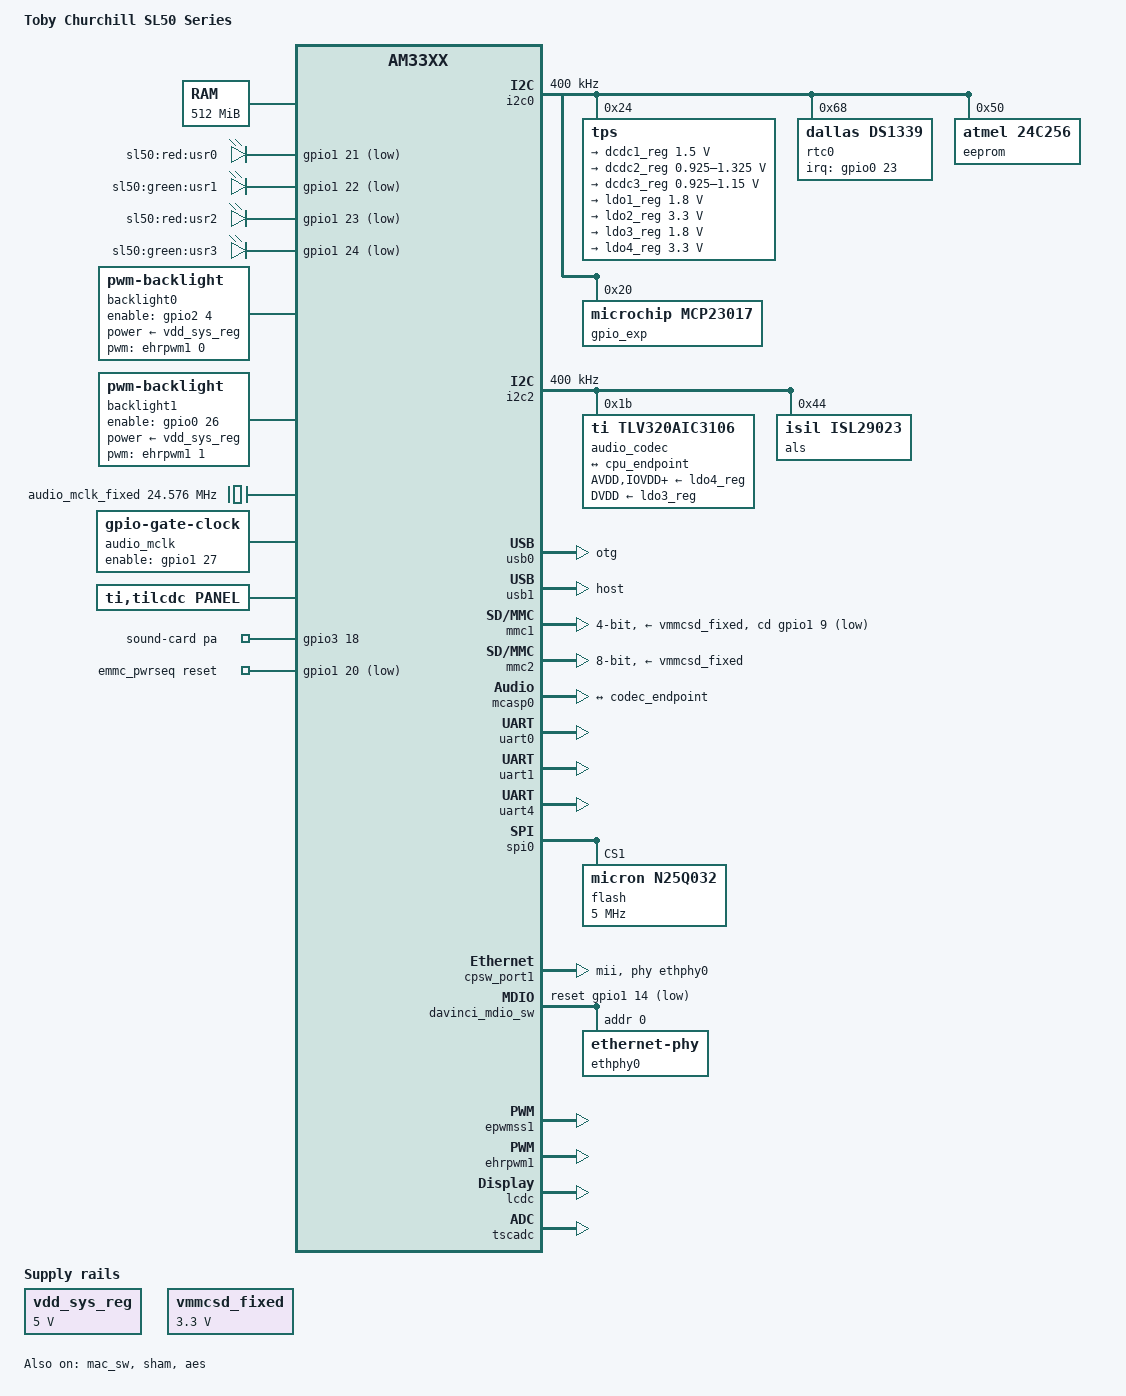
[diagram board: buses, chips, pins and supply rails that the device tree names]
/dts-v1/;
#include "am33xx.dtsi"
#include <dt-bindings/pwm/pwm.h>
#include <dt-bindings/interrupt-controller/irq.h>
/ {
	model = "Toby Churchill SL50 Series";
	compatible = "tcl,am335x-sl50", "ti,am33xx";
	cpus {
		cpu@0 {
			cpu0-supply = <&dcdc2_reg>;
		};
	};
	memory@80000000 {
		device_type = "memory";
		reg = <0x80000000 0x20000000>;  
	};
	chosen {
		stdout-path = &uart0;
	};
	leds {
		compatible = "gpio-leds";
		pinctrl-names = "default";
		pinctrl-0 = <&led_pins>;
		led0 {
			label = "sl50:red:usr0";
			gpios = <&gpio1 21 GPIO_ACTIVE_LOW>;
			default-state = "off";
		};
		led1 {
			label = "sl50:green:usr1";
			gpios = <&gpio1 22 GPIO_ACTIVE_LOW>;
			default-state = "off";
		};
		led2 {
			label = "sl50:red:usr2";
			gpios = <&gpio1 23 GPIO_ACTIVE_LOW>;
			default-state = "off";
		};
		led3 {
			label = "sl50:green:usr3";
			gpios = <&gpio1 24 GPIO_ACTIVE_LOW>;
			default-state = "off";
		};
	};
	backlight0: disp0 {
		compatible = "pwm-backlight";
		pinctrl-names = "default";
		pinctrl-0 = <&backlight0_pins>;
		pwms = <&ehrpwm1 0 500000 PWM_POLARITY_INVERTED>;
		brightness-levels = < 0  1  2  3  4  5  6  7  8  9
				     10 11 12 13 14 15 16 17 18 19
				     20 21 22 23 24 25 26 27 28 29
				     30 31 32 33 34 35 36 37 38 39
				     40 41 42 43 44 45 46 47 48 49
				     50 51 52 53 54 55 56 57 58 59
				     60 61 62 63 64 65 66 67 68 69
				     70 71 72 73 74 75 76 77 78 79
				     80 81 82 83 84 85 86 87 88 89
				     90 91 92 93 94 95 96 97 98 99
				    100>;
		default-brightness-level = <50>;
		enable-gpios = <&gpio2 4 GPIO_ACTIVE_HIGH>;
		power-supply = <&vdd_sys_reg>;
	};
	backlight1: disp1 {
		compatible = "pwm-backlight";
		pinctrl-names = "default";
		pinctrl-0 = <&backlight1_pins>;
		pwms = <&ehrpwm1 1 500000 PWM_POLARITY_INVERTED>;
		brightness-levels = < 0  1  2  3  4  5  6  7  8  9
				     10 11 12 13 14 15 16 17 18 19
				     20 21 22 23 24 25 26 27 28 29
				     30 31 32 33 34 35 36 37 38 39
				     40 41 42 43 44 45 46 47 48 49
				     50 51 52 53 54 55 56 57 58 59
				     60 61 62 63 64 65 66 67 68 69
				     70 71 72 73 74 75 76 77 78 79
				     80 81 82 83 84 85 86 87 88 89
				     90 91 92 93 94 95 96 97 98 99
				    100>;
		default-brightness-level = <50>;
		enable-gpios = <&gpio0 26 GPIO_ACTIVE_HIGH>;
		power-supply = <&vdd_sys_reg>;
	};
	clocks {
		compatible = "simple-bus";
		#address-cells = <1>;
		#size-cells = <0>;
		audio_mclk_fixed: oscillator@0 {
			compatible = "fixed-clock";
			#clock-cells = <0>;
			clock-frequency  = <24576000>;	 
		};
		audio_mclk: audio_mclk_gate@0 {
			compatible = "gpio-gate-clock";
			#clock-cells = <0>;
			pinctrl-names = "default";
			pinctrl-0 = <&audio_mclk_pins>;
			clocks = <&audio_mclk_fixed>;
			enable-gpios = <&gpio1 27 0>;
		};
	};
	panel: lcd_panel {
		compatible = "ti,tilcdc,panel";
		pinctrl-names = "default";
		pinctrl-0 = <&lcd_pins>;
		panel-info {
			ac-bias = <255>;
			ac-bias-intrpt = <0>;
			dma-burst-sz = <16>;
			bpp = <16>;
			fdd = <0x80>;
			tft-alt-mode = <0>;
			mono-8bit-mode = <0>;
			sync-edge = <0>;
			sync-ctrl = <1>;
			raster-order = <0>;
			fifo-th = <0>;
		};
		display-timings {
			native-mode = <&timing0>;
			timing0: 960x128 {
				clock-frequency = <18000000>;
				hactive = <960>;
				vactive = <272>;
				hback-porch = <40>;
				hfront-porch = <16>;
				hsync-len = <24>;
				hsync-active = <0>;
				vback-porch = <3>;
				vfront-porch = <8>;
				vsync-len = <4>;
				vsync-active = <0>;
			};
		};
	};
	sound {
		compatible = "audio-graph-card";
		label = "sound-card";
		pinctrl-names = "default";
		pinctrl-0 = <&audio_pa_pins>;
		widgets = "Headphone", "Headphone Jack",
			  "Speaker", "Speaker External",
			  "Line", "Line In",
			  "Microphone", "Microphone Jack";
		routing = "Headphone Jack",	"HPLOUT",
			  "Headphone Jack",	"HPROUT",
			  "Amplifier",		"MONO_LOUT",
			  "Speaker External",	"Amplifier",
			  "LINE1R",		"Line In",
			  "LINE1L",		"Line In",
			  "MIC3L",		"Microphone Jack",
			  "MIC3R",		"Microphone Jack",
			  "Microphone Jack",	"Mic Bias";
		dais = <&cpu_port>;
		pa-gpios = <&gpio3 18 GPIO_ACTIVE_HIGH>;
	};
	emmc_pwrseq: pwrseq@0 {
		compatible = "mmc-pwrseq-emmc";
		pinctrl-names = "default";
		pinctrl-0 = <&emmc_pwrseq_pins>;
		reset-gpios = <&gpio1 20 GPIO_ACTIVE_LOW>;
	};
	vdd_sys_reg: regulator@0 {
		compatible = "regulator-fixed";
		regulator-name = "vdd_sys_reg";
		regulator-min-microvolt = <5000000>;
		regulator-max-microvolt = <5000000>;
		regulator-always-on;
	};
	vmmcsd_fixed: fixedregulator0 {
		compatible = "regulator-fixed";
		regulator-name = "vmmcsd_fixed";
		regulator-min-microvolt = <3300000>;
		regulator-max-microvolt = <3300000>;
	};
};
&am33xx_pinmux {
	pinctrl-names = "default";
	pinctrl-0 = <&lwb_pins>;
	audio_pins: audio-pins {
		pinctrl-single,pins = <
			AM33XX_PADCONF(AM335X_PIN_MCASP0_AHCLKX, PIN_INPUT_PULLDOWN, MUX_MODE0)
			AM33XX_PADCONF(AM335X_PIN_MCASP0_FSX, PIN_INPUT_PULLDOWN, MUX_MODE0)
			AM33XX_PADCONF(AM335X_PIN_MCASP0_ACLKX, PIN_INPUT_PULLDOWN, MUX_MODE0)
			AM33XX_PADCONF(AM335X_PIN_MCASP0_AXR0, PIN_INPUT_PULLDOWN, MUX_MODE0)
			AM33XX_PADCONF(AM335X_PIN_MCASP0_AHCLKR, PIN_OUTPUT_PULLDOWN, MUX_MODE2)
		>;
	};
	audio_pa_pins: audio-pa-pins {
		pinctrl-single,pins = <
			AM33XX_PADCONF(AM335X_PIN_MCASP0_ACLKR, PIN_INPUT_PULLDOWN, MUX_MODE7)	 
		>;
	};
	audio_mclk_pins: audio-mclk-pins {
		pinctrl-single,pins = <
			AM33XX_PADCONF(AM335X_PIN_GPMC_A11, PIN_INPUT_PULLDOWN, MUX_MODE7)	 
		>;
	};
	backlight0_pins: backlight0-pins {
		pinctrl-single,pins = <
			AM33XX_PADCONF(AM335X_PIN_GPMC_WEN, PIN_OUTPUT, MUX_MODE7)	 
		>;
	};
	backlight1_pins: backlight1-pins {
		pinctrl-single,pins = <
			AM33XX_PADCONF(AM335X_PIN_GPMC_AD10, PIN_OUTPUT, MUX_MODE7)      
		>;
	};
	lcd_pins: lcd-pins {
		pinctrl-single,pins = <
			AM33XX_PADCONF(AM335X_PIN_LCD_DATA0, PIN_OUTPUT, MUX_MODE0)
			AM33XX_PADCONF(AM335X_PIN_LCD_DATA1, PIN_OUTPUT, MUX_MODE0)
			AM33XX_PADCONF(AM335X_PIN_LCD_DATA2, PIN_OUTPUT, MUX_MODE0)
			AM33XX_PADCONF(AM335X_PIN_LCD_DATA3, PIN_OUTPUT, MUX_MODE0)
			AM33XX_PADCONF(AM335X_PIN_LCD_DATA4, PIN_OUTPUT, MUX_MODE0)
			AM33XX_PADCONF(AM335X_PIN_LCD_DATA5, PIN_OUTPUT, MUX_MODE0)
			AM33XX_PADCONF(AM335X_PIN_LCD_DATA6, PIN_OUTPUT, MUX_MODE0)
			AM33XX_PADCONF(AM335X_PIN_LCD_DATA7, PIN_OUTPUT, MUX_MODE0)
			AM33XX_PADCONF(AM335X_PIN_LCD_DATA8, PIN_OUTPUT, MUX_MODE0)
			AM33XX_PADCONF(AM335X_PIN_LCD_DATA9, PIN_OUTPUT, MUX_MODE0)
			AM33XX_PADCONF(AM335X_PIN_LCD_DATA10, PIN_OUTPUT, MUX_MODE0)
			AM33XX_PADCONF(AM335X_PIN_LCD_DATA11, PIN_OUTPUT, MUX_MODE0)
			AM33XX_PADCONF(AM335X_PIN_LCD_DATA12, PIN_OUTPUT, MUX_MODE0)
			AM33XX_PADCONF(AM335X_PIN_LCD_DATA13, PIN_OUTPUT, MUX_MODE0)
			AM33XX_PADCONF(AM335X_PIN_LCD_DATA14, PIN_OUTPUT, MUX_MODE0)
			AM33XX_PADCONF(AM335X_PIN_LCD_DATA15, PIN_OUTPUT, MUX_MODE0)
			AM33XX_PADCONF(AM335X_PIN_LCD_VSYNC, PIN_OUTPUT_PULLDOWN, MUX_MODE0)
			AM33XX_PADCONF(AM335X_PIN_LCD_HSYNC, PIN_OUTPUT_PULLDOWN, MUX_MODE0)
			AM33XX_PADCONF(AM335X_PIN_LCD_PCLK, PIN_OUTPUT_PULLDOWN, MUX_MODE0)
			AM33XX_PADCONF(AM335X_PIN_LCD_AC_BIAS_EN, PIN_OUTPUT_PULLDOWN, MUX_MODE0)
		>;
	};
	led_pins: led-pins {
		pinctrl-single,pins = <
			AM33XX_PADCONF(AM335X_PIN_GPMC_A5, PIN_OUTPUT, MUX_MODE7)	 
			AM33XX_PADCONF(AM335X_PIN_GPMC_A6, PIN_OUTPUT, MUX_MODE7)	 
			AM33XX_PADCONF(AM335X_PIN_GPMC_A7, PIN_OUTPUT, MUX_MODE7)	 
			AM33XX_PADCONF(AM335X_PIN_GPMC_A8, PIN_OUTPUT, MUX_MODE7)	 
		>;
	};
	uart0_pins: uart0-pins {
		pinctrl-single,pins = <
			AM33XX_PADCONF(AM335X_PIN_UART0_RXD, PIN_INPUT_PULLUP, MUX_MODE0)
			AM33XX_PADCONF(AM335X_PIN_UART0_TXD, PIN_OUTPUT_PULLDOWN, MUX_MODE0)
		>;
	};
	uart1_pins: uart1-pins {
		pinctrl-single,pins = <
			AM33XX_PADCONF(AM335X_PIN_UART1_RXD, PIN_INPUT_PULLUP, MUX_MODE0)
			AM33XX_PADCONF(AM335X_PIN_UART1_TXD, PIN_OUTPUT_PULLDOWN, MUX_MODE0)
		>;
	};
	uart4_pins: uart4-pins {
		pinctrl-single,pins = <
			AM33XX_PADCONF(AM335X_PIN_GPMC_WAIT0, PIN_INPUT_PULLUP, MUX_MODE6)	 
			AM33XX_PADCONF(AM335X_PIN_GPMC_WPN, PIN_OUTPUT_PULLDOWN, MUX_MODE6)	 
		>;
	};
	i2c0_pins: i2c0-pins {
		pinctrl-single,pins = <
			AM33XX_PADCONF(AM335X_PIN_I2C0_SDA, PIN_INPUT_PULLUP, MUX_MODE0)
			AM33XX_PADCONF(AM335X_PIN_I2C0_SCL, PIN_INPUT_PULLUP, MUX_MODE0)
		>;
	};
	i2c2_pins: i2c2-pins {
		pinctrl-single,pins = <
			AM33XX_PADCONF(AM335X_PIN_UART1_CTSN, PIN_INPUT_PULLUP, MUX_MODE3)	 
			AM33XX_PADCONF(AM335X_PIN_UART1_RTSN, PIN_INPUT_PULLUP, MUX_MODE3)	 
		>;
	};
	cpsw_default: cpsw-default-pins {
		pinctrl-single,pins = <
			AM33XX_PADCONF(AM335X_PIN_MII1_RX_ER, PIN_INPUT_PULLUP, MUX_MODE0)
			AM33XX_PADCONF(AM335X_PIN_MII1_TX_EN, PIN_OUTPUT_PULLDOWN, MUX_MODE0)
			AM33XX_PADCONF(AM335X_PIN_MII1_RX_DV, PIN_INPUT_PULLUP, MUX_MODE0)
			AM33XX_PADCONF(AM335X_PIN_MII1_TXD3, PIN_OUTPUT_PULLDOWN, MUX_MODE0)
			AM33XX_PADCONF(AM335X_PIN_MII1_TXD2, PIN_OUTPUT_PULLDOWN, MUX_MODE0)
			AM33XX_PADCONF(AM335X_PIN_MII1_TXD1, PIN_OUTPUT_PULLDOWN, MUX_MODE0)
			AM33XX_PADCONF(AM335X_PIN_MII1_TXD0, PIN_OUTPUT_PULLDOWN, MUX_MODE0)
			AM33XX_PADCONF(AM335X_PIN_MII1_TX_CLK, PIN_INPUT_PULLUP, MUX_MODE0)
			AM33XX_PADCONF(AM335X_PIN_MII1_RX_CLK, PIN_INPUT_PULLUP, MUX_MODE0)
			AM33XX_PADCONF(AM335X_PIN_MII1_RXD3, PIN_INPUT_PULLUP, MUX_MODE0)
			AM33XX_PADCONF(AM335X_PIN_MII1_RXD2, PIN_INPUT_PULLUP, MUX_MODE0)
			AM33XX_PADCONF(AM335X_PIN_MII1_RXD1, PIN_INPUT_PULLUP, MUX_MODE0)
			AM33XX_PADCONF(AM335X_PIN_MII1_RXD0, PIN_INPUT_PULLUP, MUX_MODE0)
		>;
	};
	cpsw_sleep: cpsw-sleep-pins {
		pinctrl-single,pins = <
			AM33XX_PADCONF(AM335X_PIN_MII1_RX_ER, PIN_INPUT_PULLDOWN, MUX_MODE7)
			AM33XX_PADCONF(AM335X_PIN_MII1_TX_EN, PIN_INPUT_PULLDOWN, MUX_MODE7)
			AM33XX_PADCONF(AM335X_PIN_MII1_RX_DV, PIN_INPUT_PULLDOWN, MUX_MODE7)
			AM33XX_PADCONF(AM335X_PIN_MII1_TXD3, PIN_INPUT_PULLDOWN, MUX_MODE7)
			AM33XX_PADCONF(AM335X_PIN_MII1_TXD2, PIN_INPUT_PULLDOWN, MUX_MODE7)
			AM33XX_PADCONF(AM335X_PIN_MII1_TXD1, PIN_INPUT_PULLDOWN, MUX_MODE7)
			AM33XX_PADCONF(AM335X_PIN_MII1_TXD0, PIN_INPUT_PULLDOWN, MUX_MODE7)
			AM33XX_PADCONF(AM335X_PIN_MII1_TX_CLK, PIN_INPUT_PULLDOWN, MUX_MODE7)
			AM33XX_PADCONF(AM335X_PIN_MII1_RX_CLK, PIN_INPUT_PULLDOWN, MUX_MODE7)
			AM33XX_PADCONF(AM335X_PIN_MII1_RXD3, PIN_INPUT_PULLDOWN, MUX_MODE7)
			AM33XX_PADCONF(AM335X_PIN_MII1_RXD2, PIN_INPUT_PULLDOWN, MUX_MODE7)
			AM33XX_PADCONF(AM335X_PIN_MII1_RXD1, PIN_INPUT_PULLDOWN, MUX_MODE7)
			AM33XX_PADCONF(AM335X_PIN_MII1_RXD0, PIN_INPUT_PULLDOWN, MUX_MODE7)
		>;
	};
	davinci_mdio_default: davinci-mdio-default-pins {
		pinctrl-single,pins = <
			AM33XX_PADCONF(AM335X_PIN_MDIO, PIN_INPUT_PULLUP | SLEWCTRL_FAST, MUX_MODE0)
			AM33XX_PADCONF(AM335X_PIN_MDC, PIN_OUTPUT_PULLUP, MUX_MODE0)
			AM33XX_PADCONF(AM335X_PIN_GPMC_AD14, PIN_INPUT_PULLUP, MUX_MODE7)	 
		>;
	};
	davinci_mdio_sleep: davinci-mdio-sleep-pins {
		pinctrl-single,pins = <
			AM33XX_PADCONF(AM335X_PIN_MDIO, PIN_INPUT_PULLDOWN, MUX_MODE7)
			AM33XX_PADCONF(AM335X_PIN_MDC, PIN_INPUT_PULLDOWN, MUX_MODE7)
		>;
	};
	mmc1_pins: mmc1-pins {
		pinctrl-single,pins = <
			AM33XX_PADCONF(AM335X_PIN_UART0_RTSN, PIN_INPUT, MUX_MODE7)		 
		>;
	};
	emmc_pwrseq_pins: emmc-pwrseq-pins {
		pinctrl-single,pins = <
			AM33XX_PADCONF(AM335X_PIN_GPMC_A4, PIN_OUTPUT_PULLUP, MUX_MODE7)	 
		>;
	};
	emmc_pins: emmc-pins {
		pinctrl-single,pins = <
			AM33XX_PADCONF(AM335X_PIN_GPMC_CSN1, PIN_INPUT_PULLUP, MUX_MODE2)	 
			AM33XX_PADCONF(AM335X_PIN_GPMC_CSN2, PIN_INPUT_PULLUP, MUX_MODE2)	 
			AM33XX_PADCONF(AM335X_PIN_GPMC_AD0, PIN_INPUT_PULLUP, MUX_MODE1)	 
			AM33XX_PADCONF(AM335X_PIN_GPMC_AD1, PIN_INPUT_PULLUP, MUX_MODE1)	 
			AM33XX_PADCONF(AM335X_PIN_GPMC_AD2, PIN_INPUT_PULLUP, MUX_MODE1)	 
			AM33XX_PADCONF(AM335X_PIN_GPMC_AD3, PIN_INPUT_PULLUP, MUX_MODE1)	 
			AM33XX_PADCONF(AM335X_PIN_GPMC_AD4, PIN_INPUT_PULLUP, MUX_MODE1)	 
			AM33XX_PADCONF(AM335X_PIN_GPMC_AD5, PIN_INPUT_PULLUP, MUX_MODE1) 	 
			AM33XX_PADCONF(AM335X_PIN_GPMC_AD6, PIN_INPUT_PULLUP, MUX_MODE1)	 
			AM33XX_PADCONF(AM335X_PIN_GPMC_AD7, PIN_INPUT_PULLUP, MUX_MODE1)	 
		>;
	};
	ehrpwm1_pins: ehrpwm1a-pins {
		pinctrl-single,pins = <
			AM33XX_PADCONF(AM335X_PIN_GPMC_A2, PIN_OUTPUT, MUX_MODE6)	 
			AM33XX_PADCONF(AM335X_PIN_GPMC_A3, PIN_OUTPUT, MUX_MODE6)	 
		>;
	};
	rtc0_irq_pins: rtc0-irq-pins {
		pinctrl-single,pins = <
			AM33XX_PADCONF(AM335X_PIN_GPMC_AD9, PIN_INPUT_PULLUP, MUX_MODE7)      
		>;
	};
	spi0_pins: spi0-pins {
		pinctrl-single,pins = <
			AM33XX_PADCONF(AM335X_PIN_SPI0_D0, PIN_INPUT_PULLUP, MUX_MODE0)	 
			AM33XX_PADCONF(AM335X_PIN_SPI0_D1, PIN_INPUT_PULLUP, MUX_MODE0)	 
			AM33XX_PADCONF(AM335X_PIN_SPI0_SCLK, PIN_INPUT_PULLUP, MUX_MODE0)
			AM33XX_PADCONF(AM335X_PIN_SPI0_CS0, PIN_INPUT_PULLUP, MUX_MODE0)	 
			AM33XX_PADCONF(AM335X_PIN_SPI0_CS1, PIN_INPUT_PULLUP, MUX_MODE0)	 
		>;
	};
	lwb_pins: lwb-pins {
		pinctrl-single,pins = <
			AM33XX_PADCONF(AM335X_PIN_GPMC_AD12, PIN_INPUT_PULLUP, MUX_MODE7)	 
			AM33XX_PADCONF(AM335X_PIN_GPMC_AD13, PIN_INPUT_PULLUP, MUX_MODE7)	 
			AM33XX_PADCONF(AM335X_PIN_GPMC_A1, PIN_INPUT_PULLUP, MUX_MODE7)	 
			AM33XX_PADCONF(AM335X_PIN_GPMC_A0, PIN_INPUT_PULLUP, MUX_MODE7)	 
			AM33XX_PADCONF(AM335X_PIN_GPMC_AD15, PIN_INPUT_PULLUP, MUX_MODE7)	 
			AM33XX_PADCONF(AM335X_PIN_GPMC_AD8, PIN_INPUT_PULLUP, MUX_MODE7)	 
			AM33XX_PADCONF(AM335X_PIN_GPMC_A0, PIN_INPUT_PULLUP, MUX_MODE7)	 
			AM33XX_PADCONF(AM335X_PIN_GPMC_A1, PIN_INPUT_PULLDOWN, MUX_MODE7)	 
			AM33XX_PADCONF(AM335X_PIN_GPMC_A9, PIN_INPUT_PULLUP, MUX_MODE7)	 
			AM33XX_PADCONF(AM335X_PIN_GPMC_A10, PIN_INPUT_PULLDOWN, MUX_MODE7)	 
		>;
	};
};
&i2c0 {
	status = "okay";
	pinctrl-names = "default";
	pinctrl-0 = <&i2c0_pins>;
	clock-frequency = <400000>;
	tps: tps@24 {
		reg = <0x24>;
	};
	rtc0: rtc@68 {
		compatible = "dallas,ds1339";
		pinctrl-names = "default";
		pinctrl-0 = <&rtc0_irq_pins>;
		interrupt-parent = <&gpio0>;
		interrupts = <23 IRQ_TYPE_EDGE_FALLING>;  
		wakeup-source;
		trickle-resistor-ohms = <2000>;
		reg = <0x68>;
	};
	eeprom: eeprom@50 {
		compatible = "atmel,24c256";
		reg = <0x50>;
	};
	gpio_exp: mcp23017@20 {
		compatible = "microchip,mcp23017";
		reg = <0x20>;
	};
};
&i2c2 {
	status = "okay";
	pinctrl-names = "default";
	pinctrl-0 = <&i2c2_pins>;
	clock-frequency = <400000>;
	audio_codec: tlv320aic3106@1b {
		status = "okay";
		compatible = "ti,tlv320aic3106";
		#sound-dai-cells = <0>;
		reg = <0x1b>;
		ai3x-micbias-vg = <2>;   
		AVDD-supply = <&ldo4_reg>;
		IOVDD-supply = <&ldo4_reg>;
		DRVDD-supply = <&ldo4_reg>;
		DVDD-supply = <&ldo3_reg>;
		codec_port: port {
			codec_endpoint: endpoint {
				remote-endpoint = <&cpu_endpoint>;
				clocks = <&audio_mclk>;
			};
		};
	};
	als: isl29023@44 {
		compatible = "isil,isl29023";
		reg = <0x44>;
	};
};
&rtc {
	status = "disabled";
};
&usb0 {
	dr_mode = "otg";
};
&usb1 {
	dr_mode = "host";
};
&mmc1 {
	status = "okay";
	pinctrl-names = "default";
	pinctrl-0 = <&mmc1_pins>;
	bus-width = <4>;
	cd-gpios = <&gpio1 9 GPIO_ACTIVE_LOW>;
	vmmc-supply = <&vmmcsd_fixed>;
};
&mmc2 {
	status = "okay";
	pinctrl-names = "default";
	pinctrl-0 = <&emmc_pins>;
	bus-width = <8>;
	vmmc-supply = <&vmmcsd_fixed>;
	mmc-pwrseq = <&emmc_pwrseq>;
};
&mcasp0 {
	status = "okay";
	pinctrl-names = "default";
	pinctrl-0 = <&audio_pins>;
	#sound-dai-cells = <0>;
	op-mode = <0>;   
	tdm-slots = <2>;
	serial-dir = <   
		0 0 1 2
	>;
	tx-num-evt = <32>;
	rx-num-evt = <32>;
	cpu_port: port {
		cpu_endpoint: endpoint {
			remote-endpoint = <&codec_endpoint>;
			dai-format = "dsp_b";
			bitclock-master = <&codec_port>;
			frame-master = <&codec_port>;
			bitclock-inversion;
			clocks = <&audio_mclk>;
		};
	};
};
&uart0 {
	status = "okay";
	pinctrl-names = "default";
	pinctrl-0 = <&uart0_pins>;
};
&uart1 {
	status = "okay";
	pinctrl-names = "default";
	pinctrl-0 = <&uart1_pins>;
};
&uart4 {
	status = "okay";
	pinctrl-names = "default";
	pinctrl-0 = <&uart4_pins>;
};
&spi0 {
	status = "okay";
	pinctrl-names = "default";
	pinctrl-0 = <&spi0_pins>;
	flash: flash@1 {
		#address-cells = <1>;
		#size-cells = <1>;
		compatible = "micron,n25q032";
		reg = <1>;
		spi-max-frequency = <5000000>;
	};
};
#include "../../tps65217.dtsi"
&tps {
	ti,pmic-shutdown-controller;
	interrupt-parent = <&intc>;
	interrupts = <7>;	 
	regulators {
		dcdc1_reg: regulator@0 {
			regulator-min-microvolt = <1500000>;
			regulator-max-microvolt = <1500000>;
			regulator-always-on;
		};
		dcdc2_reg: regulator@1 {
			regulator-name = "vdd_mpu";
			regulator-min-microvolt = <925000>;
			regulator-max-microvolt = <1325000>;
			regulator-boot-on;
			regulator-always-on;
		};
		dcdc3_reg: regulator@2 {
			regulator-name = "vdd_core";
			regulator-min-microvolt = <925000>;
			regulator-max-microvolt = <1150000>;
			regulator-boot-on;
			regulator-always-on;
		};
		ldo1_reg: regulator@3 {
			regulator-always-on;
			regulator-min-microvolt = <1800000>;
			regulator-max-microvolt = <1800000>;
		};
		ldo2_reg: regulator@4 {
			regulator-always-on;
			regulator-min-microvolt = <3300000>;
			regulator-max-microvolt = <3300000>;
		};
		ldo3_reg: regulator@5 {
			regulator-min-microvolt = <1800000>;
			regulator-max-microvolt = <1800000>;
			regulator-always-on;
		};
		ldo4_reg: regulator@6 {
			regulator-min-microvolt = <3300000>;
			regulator-max-microvolt = <3300000>;
			regulator-always-on;
		};
	};
};
&cpsw_port1 {
	phy-mode = "mii";
	phy-handle = <&ethphy0>;
	ti,dual-emac-pvid = <1>;
};
&cpsw_port2 {
	status = "disabled";
};
&mac_sw {
	status = "okay";
	pinctrl-names = "default", "sleep";
	pinctrl-0 = <&cpsw_default>;
	pinctrl-1 = <&cpsw_sleep>;
};
&davinci_mdio_sw {
	pinctrl-names = "default", "sleep";
	pinctrl-0 = <&davinci_mdio_default>;
	pinctrl-1 = <&davinci_mdio_sleep>;
	reset-gpios = <&gpio1 14 GPIO_ACTIVE_LOW>;
	reset-delay-us = <100>;    
	ethphy0: ethernet-phy@0 {
		reg = <0>;
	};
};
&sham {
	status = "okay";
};
&aes {
	status = "okay";
};
&epwmss1 {
	status = "okay";
};
&ehrpwm1 {
	status = "okay";
	pinctrl-names = "default";
	pinctrl-0 = <&ehrpwm1_pins>;
};
&lcdc {
	status = "okay";
};
&tscadc {
	status = "okay";
};
&am335x_adc {
	ti,adc-channels = <0 1 2 3 4 5 6 7>;
};
